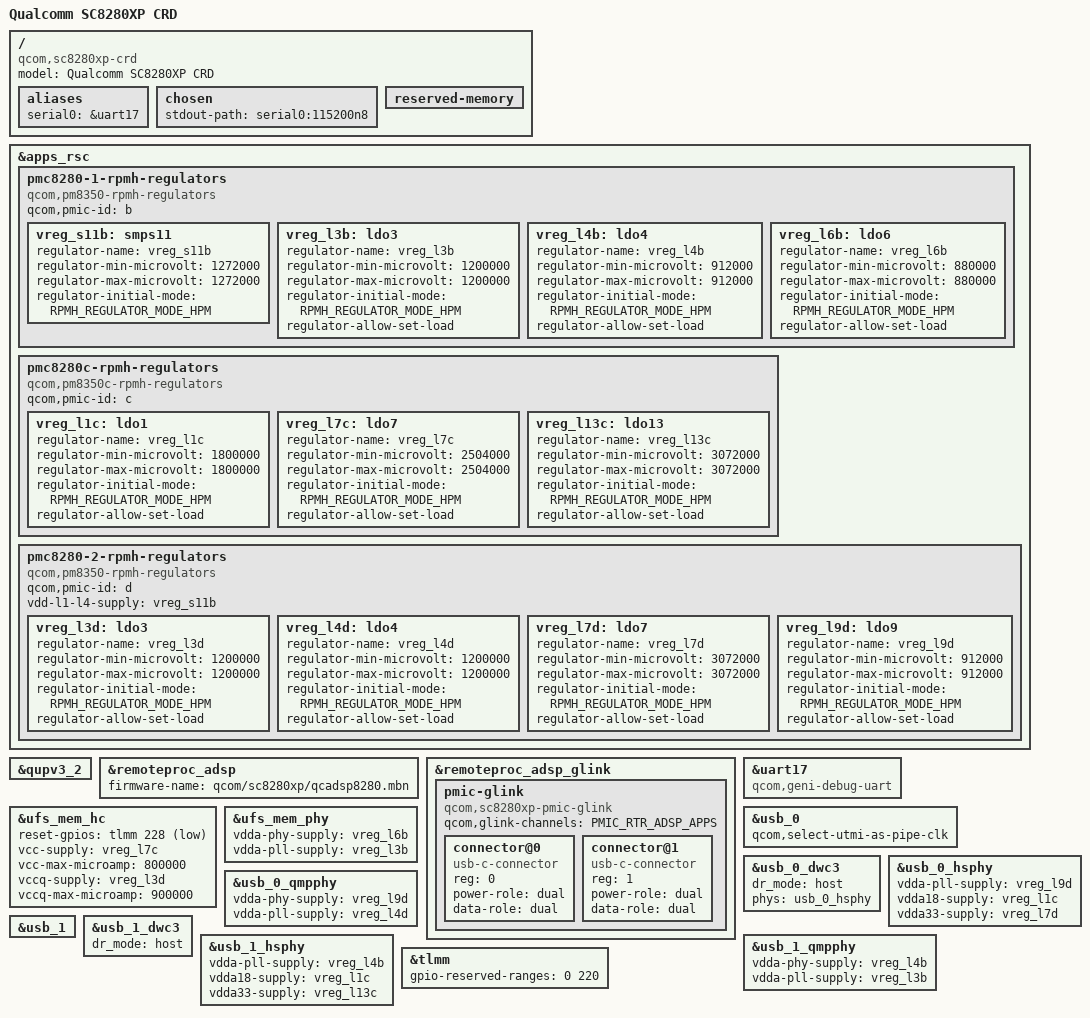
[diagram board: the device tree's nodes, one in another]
// SPDX-License-Identifier: BSD-3-Clause
/*
 * Copyright (c) 2017-2019, The Linux Foundation. All rights reserved.
 * Copyright (c) 2020-2021, Linaro Limited
 */

/dts-v1/;

#include <dt-bindings/gpio/gpio.h>
#include <dt-bindings/input/gpio-keys.h>
#include <dt-bindings/input/input.h>
#include <dt-bindings/regulator/qcom,rpmh-regulator.h>

#include "sc8280xp.dtsi"

/ {
	model = "Qualcomm SC8280XP CRD";
	compatible = "qcom,sc8280xp-crd", "qcom,sc8280xp";

	aliases {
		serial0 = &uart17;
	};

	chosen {
		stdout-path = "serial0:115200n8";
	};

	reserved-memory {
	};
};

&apps_rsc {
	pmc8280-1-rpmh-regulators {
		compatible = "qcom,pm8350-rpmh-regulators";
		qcom,pmic-id = "b";

		vreg_s11b: smps11 {
			regulator-name = "vreg_s11b";
			regulator-min-microvolt = <1272000>;
			regulator-max-microvolt = <1272000>;
			regulator-initial-mode = <RPMH_REGULATOR_MODE_HPM>;
		};

		vreg_l3b: ldo3 {
			regulator-name = "vreg_l3b";
			regulator-min-microvolt = <1200000>;
			regulator-max-microvolt = <1200000>;
			regulator-initial-mode = <RPMH_REGULATOR_MODE_HPM>;
			regulator-allow-set-load;
		};

		vreg_l4b: ldo4 {
			regulator-name = "vreg_l4b";
			regulator-min-microvolt = <912000>;
			regulator-max-microvolt = <912000>;
			regulator-initial-mode = <RPMH_REGULATOR_MODE_HPM>;
			regulator-allow-set-load;
		};

		vreg_l6b: ldo6 {
			regulator-name = "vreg_l6b";
			regulator-min-microvolt = <880000>;
			regulator-max-microvolt = <880000>;
			regulator-initial-mode = <RPMH_REGULATOR_MODE_HPM>;
			regulator-allow-set-load;
		};
	};

	pmc8280c-rpmh-regulators {
		compatible = "qcom,pm8350c-rpmh-regulators";
		qcom,pmic-id = "c";

		vreg_l1c: ldo1 {
			regulator-name = "vreg_l1c";
			regulator-min-microvolt = <1800000>;
			regulator-max-microvolt = <1800000>;
			regulator-initial-mode = <RPMH_REGULATOR_MODE_HPM>;
			regulator-allow-set-load;
		};

		vreg_l7c: ldo7 {
			regulator-name = "vreg_l7c";
			regulator-min-microvolt = <2504000>;
			regulator-max-microvolt = <2504000>;
			regulator-initial-mode = <RPMH_REGULATOR_MODE_HPM>;
			regulator-allow-set-load;
		};

		vreg_l13c: ldo13 {
			regulator-name = "vreg_l13c";
			regulator-min-microvolt = <3072000>;
			regulator-max-microvolt = <3072000>;
			regulator-initial-mode = <RPMH_REGULATOR_MODE_HPM>;
			regulator-allow-set-load;
		};
	};

	pmc8280-2-rpmh-regulators {
		compatible = "qcom,pm8350-rpmh-regulators";
		qcom,pmic-id = "d";

		vdd-l1-l4-supply = <&vreg_s11b>;

		vreg_l3d: ldo3 {
			regulator-name = "vreg_l3d";
			regulator-min-microvolt = <1200000>;
			regulator-max-microvolt = <1200000>;
			regulator-initial-mode = <RPMH_REGULATOR_MODE_HPM>;
			regulator-allow-set-load;
		};

		vreg_l4d: ldo4 {
			regulator-name = "vreg_l4d";
			regulator-min-microvolt = <1200000>;
			regulator-max-microvolt = <1200000>;
			regulator-initial-mode = <RPMH_REGULATOR_MODE_HPM>;
			regulator-allow-set-load;
		};

		vreg_l7d: ldo7 {
			regulator-name = "vreg_l7d";
			regulator-min-microvolt = <3072000>;
			regulator-max-microvolt = <3072000>;
			regulator-initial-mode = <RPMH_REGULATOR_MODE_HPM>;
			regulator-allow-set-load;
		};

		vreg_l9d: ldo9 {
			regulator-name = "vreg_l9d";
			regulator-min-microvolt = <912000>;
			regulator-max-microvolt = <912000>;
			regulator-initial-mode = <RPMH_REGULATOR_MODE_HPM>;
			regulator-allow-set-load;
		};
	};

};

&qupv3_2 {
	status = "okay";
};

&remoteproc_adsp {
	status = "okay";
	firmware-name = "qcom/sc8280xp/qcadsp8280.mbn";
};

&remoteproc_adsp_glink {
	pmic-glink {
		compatible = "qcom,sc8280xp-pmic-glink", "qcom,pmic-glink";
		qcom,glink-channels = "PMIC_RTR_ADSP_APPS";

		#address-cells = <1>;
		#size-cells = <0>;

		connector@0 {
			compatible = "usb-c-connector";
			reg = <0>;
			power-role = "dual";
			data-role = "dual";
		};

		connector@1 {
			compatible = "usb-c-connector";
			reg = <1>;
			power-role = "dual";
			data-role = "dual";
		};
	};
};

&uart17 {
	compatible = "qcom,geni-debug-uart";
	status = "okay";
};

&ufs_mem_hc {
	status = "okay";

	reset-gpios = <&tlmm 228 GPIO_ACTIVE_LOW>;

	vcc-supply = <&vreg_l7c>;
	vcc-max-microamp = <800000>;
	vccq-supply = <&vreg_l3d>;
	vccq-max-microamp = <900000>;
};

&ufs_mem_phy {
	status = "okay";

	vdda-phy-supply = <&vreg_l6b>;
	vdda-pll-supply = <&vreg_l3b>;
};

&usb_0 {
	status = "okay";

	qcom,select-utmi-as-pipe-clk;
};

&usb_0_dwc3 {
	/* TODO: Define USB-C connector properly */
	dr_mode = "host";

	phys = <&usb_0_hsphy>;
	phy-names = "usb2-phy";
};

&usb_0_hsphy {
	status = "okay";

	vdda-pll-supply = <&vreg_l9d>;
	vdda18-supply = <&vreg_l1c>;
	vdda33-supply = <&vreg_l7d>;
};

&usb_0_qmpphy {
//	status = "okay";

	vdda-phy-supply = <&vreg_l9d>;
	vdda-pll-supply = <&vreg_l4d>;
};

&usb_1 {
	status = "okay";
};

&usb_1_dwc3 {
	/* TODO: Define USB-C connector properly */
	dr_mode = "host";
};

&usb_1_hsphy {
	status = "okay";

	vdda-pll-supply = <&vreg_l4b>;
	vdda18-supply = <&vreg_l1c>;
	vdda33-supply = <&vreg_l13c>;
};

&usb_1_qmpphy {
	status = "okay";

	vdda-phy-supply = <&vreg_l4b>;
	vdda-pll-supply = <&vreg_l3b>;
};

/* PINCTRL - additions to nodes defined in sc8280xp.dtsi */

&tlmm {
	gpio-reserved-ranges = <0 220>;
};
